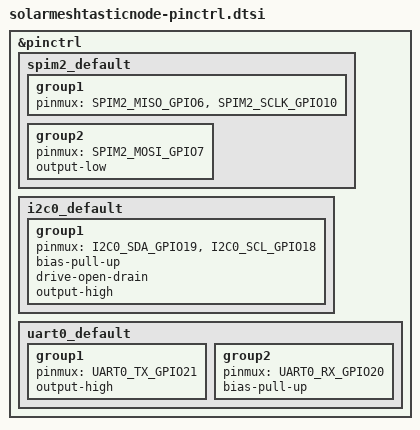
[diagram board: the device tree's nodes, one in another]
/*
 * SPDX-License-Identifier: MIT
 * Solar Meshtastic Node (Heltec HT-CT62, ESP32-C3) pin control.
 *
 * SPI2 on the native FSPI pins (SCK=10, MOSI=7, MISO=6); I2C0 SDA=19/SCL=18;
 * UART0 TX=21/RX=20.
 */

#include <zephyr/dt-bindings/pinctrl/esp-pinctrl-common.h>
#include <zephyr/dt-bindings/pinctrl/esp32c3-pinctrl.h>
#include <zephyr/dt-bindings/pinctrl/esp32c3-gpio-sigmap.h>

&pinctrl {
	spim2_default: spim2_default {
		group1 {
			pinmux = <SPIM2_MISO_GPIO6>,
				 <SPIM2_SCLK_GPIO10>;
		};

		group2 {
			pinmux = <SPIM2_MOSI_GPIO7>;
			output-low;
		};
	};

	i2c0_default: i2c0_default {
		group1 {
			pinmux = <I2C0_SDA_GPIO19>,
				 <I2C0_SCL_GPIO18>;
			bias-pull-up;
			drive-open-drain;
			output-high;
		};
	};

	uart0_default: uart0_default {
		group1 {
			pinmux = <UART0_TX_GPIO21>;
			output-high;
		};

		group2 {
			pinmux = <UART0_RX_GPIO20>;
			bias-pull-up;
		};
	};
};
